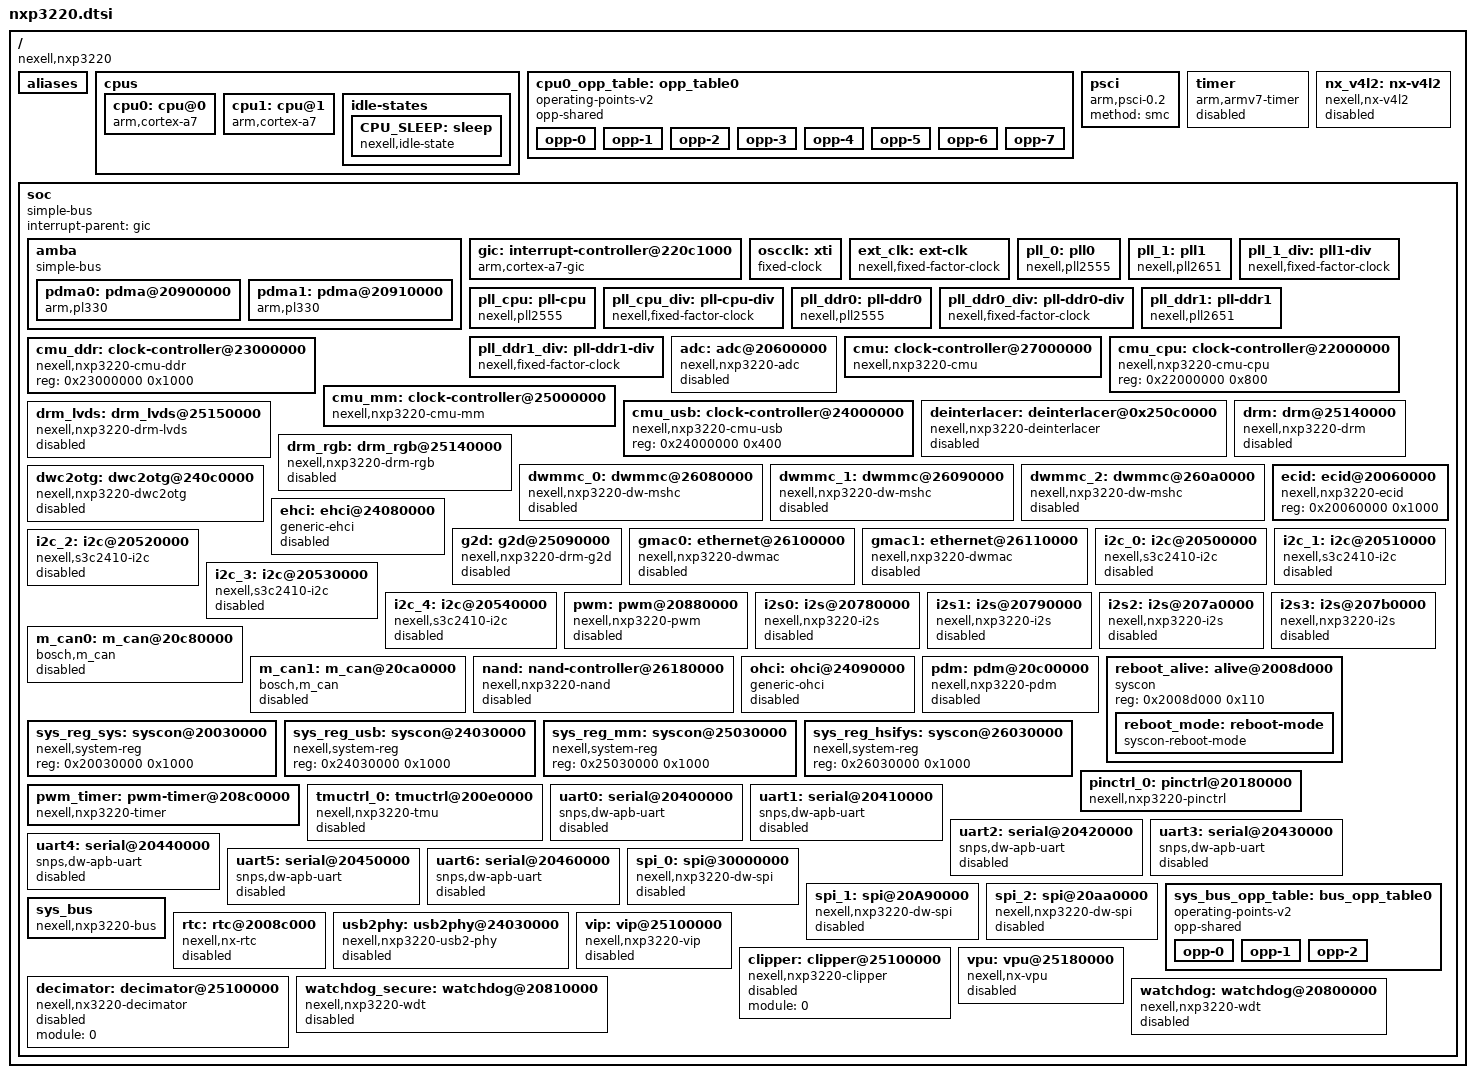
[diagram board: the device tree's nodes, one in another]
// SPDX-License-Identifier: (GPL-2.0+ OR MIT)

#include <dt-bindings/interrupt-controller/arm-gic.h>
#include <dt-bindings/clock/nxp3220-clk.h>
#include <dt-bindings/media/nxp3220-vip.h>
#include <dt-bindings/soc/nexell,boot-mode.h>
#include <dt-bindings/reset/nexell,nxp3220-reset.h>

#define CLK_SET_RATE_PARENT     (1<<2)

/ {
	compatible = "nexell,nxp3220";
	#address-cells = <0x1>;
	#size-cells = <0x1>;

	aliases {
		pinctrl0 = &pinctrl_0;
		serial0 = &uart0;
		serial1 = &uart1;
		serial2 = &uart2;
		serial3 = &uart3;
		serial4 = &uart4;
		serial5 = &uart5;
		serial6 = &uart6;
		i2c0 = &i2c_0;
		i2c1 = &i2c_1;
		i2c2 = &i2c_2;
		i2c3 = &i2c_3;
		i2c4 = &i2c_4;
		spi0 = &spi_0;
		spi1 = &spi_1;
		spi2 = &spi_2;
		ethernet0 = &gmac0;
		ethernet1 = &gmac1;
	};

	cpus {
		#address-cells = <1>;
		#size-cells = <0>;

		cpu0: cpu@0 {
			device_type = "cpu";
			compatible = "arm,cortex-a7";
			reg = <0>;
			clocks = <&pll_cpu_div 0>;
			clock-names = "cpu";
			clock-frequency = <800000000>;
			operating-points-v2 = <&cpu0_opp_table>;
			#cooling-cells = <2>;
			cpu-idle-states = <&CPU_SLEEP>;
		};

		cpu1: cpu@1 {
			device_type = "cpu";
			compatible = "arm,cortex-a7";
			reg = <1>;
			clock-frequency = <800000000>;
			operating-points-v2 = <&cpu0_opp_table>;
			cpu-idle-states = <&CPU_SLEEP>;
		};

		idle-states {
			CPU_SLEEP: sleep {
				compatible = "nexell,idle-state";
				entry-latency-us = <150>;
				exit-latency-us = <200>;
				min-residency-us = <2000>;
			};
		};
	};

	cpu0_opp_table: opp_table0 {
		compatible = "operating-points-v2";
		opp-shared;

		opp-0 {
			opp-hz = /bits/ 64 <100000000>;
			opp-microvolt = <1000000>;
		};
		opp-1 {
			opp-hz = /bits/ 64 <200000000>;
			opp-microvolt = <1000000>;
		};
		opp-2 {
			opp-hz = /bits/ 64 <300000000>;
			opp-microvolt = <1000000>;
		};
		opp-3 {
			opp-hz = /bits/ 64 <400000000>;
			opp-microvolt = <1000000>;
		};
		opp-4 {
			opp-hz = /bits/ 64 <500000000>;
			opp-microvolt = <1000000>;
		};
		opp-5 {
			opp-hz = /bits/ 64 <600000000>;
			opp-microvolt = <1000000>;
		};
		opp-6 {
			opp-hz = /bits/ 64 <700000000>;
			opp-microvolt = <1000000>;
		};
		opp-7 {
			opp-hz = /bits/ 64 <800000000>;
			opp-microvolt = <1000000>;
			opp-suspend;
		};
	};

	psci {
		compatible = "arm,psci-0.2";
		method = "smc";
	};

	timer {
		status = "disabled";

		compatible = "arm,armv7-timer";
		interrupt-parent = <&gic>;
		interrupts = <GIC_PPI 13 (GIC_CPU_MASK_SIMPLE(2) |
					  IRQ_TYPE_LEVEL_LOW)>,
			     <GIC_PPI 14 (GIC_CPU_MASK_SIMPLE(2) |
					  IRQ_TYPE_LEVEL_LOW)>,
			     <GIC_PPI 11 (GIC_CPU_MASK_SIMPLE(2) |
					  IRQ_TYPE_LEVEL_LOW)>,
			     <GIC_PPI 10 (GIC_CPU_MASK_SIMPLE(2) |
					  IRQ_TYPE_LEVEL_LOW)>;
		always-on = <1>;
		clock-frequency = <24000000>;
		arm,cpu-registers-not-fw-configured;
	};

	nx_v4l2: nx-v4l2 {
		compatible = "nexell,nx-v4l2";
		status = "disabled";
	};

	soc: soc {
		compatible = "simple-bus";
		#address-cells = <1>;
		#size-cells = <1>;
		interrupt-parent = <&gic>;
		ranges;

		amba {
			#address-cells = <1>;
			#size-cells = <1>;
			compatible = "simple-bus";
			ranges;

			pdma0: pdma@20900000 {
				compatible = "arm,pl330", "arm,primecell";
				reg = <0x20900000 0x1000>;
				clocks = <&cmu CLK_DMA0_APB>,
				         <&cmu CLK_DMA0_AXI>,
				         <&cmu CLK_DMA_BUS0_AXI>;
				clock-names = "apb_pclk", "axi_clk", "axi_bclk";
				interrupts = <GIC_SPI 35 IRQ_TYPE_NONE>, <GIC_SPI 34 IRQ_TYPE_NONE>;
				#dma-cells = <1>;
				dma-channels = <8>;
				dma-requests = <32>;
			};

			pdma1: pdma@20910000 {
				compatible = "arm,pl330", "arm,primecell";
				reg = <0x20910000 0x1000>;
				clocks = <&cmu CLK_DMA1_APB>,
				         <&cmu CLK_DMA1_AXI>,
				         <&cmu CLK_DMA_BUS0_AXI>;
				clock-names = "apb_pclk", "axi_clk", "axi_bclk";
				interrupts = <GIC_SPI 37 IRQ_TYPE_NONE>, <GIC_SPI 36 IRQ_TYPE_NONE>;
				#dma-cells = <1>;
				dma-channels = <8>;
				dma-requests = <32>;
			};
		};

		gic: interrupt-controller@220c1000 {
			compatible = "arm,cortex-a7-gic";
			reg = <0x220c1000 0x1000>,
			      <0x220c2000 0x1000>,
			      <0x220c4000 0x2000>,
			      <0x220c6000 0x2000>;
			interrupt-controller;
			#interrupt-cells = <3>;
		};

		oscclk: xti {
			compatible = "fixed-clock";
			#clock-cells = <0>;
			clock-output-names = "oscclk";
			clock-frequency =  <24000000>;
		};

		ext_clk: ext-clk {
			compatible = "nexell,fixed-factor-clock";
			#clock-cells = <0>;
			clock-div = <2>;
			clock-mult = <1>;
			clocks = <&oscclk>;
			clock-output-names = "ext_clk";
		};

		/* System bus and Io */
		pll_0: pll0 {
			compatible = "nexell,pll2555", "syscon";
			reg = <0x27020000 0x60>;
			#clock-cells = <1>;
			clocks = <&oscclk>;
			clock-output-names = "pll0";
			assigned-clocks = <&pll_0 0>;
			assigned-clock-rates = <1000000000>;
		};

		pll_1: pll1 {
			compatible = "nexell,pll2651", "syscon";
			reg = <0x27030000 0x60>;
			#clock-cells = <1>;
			clocks = <&oscclk>;
			clock-output-names = "pll1";
		};

		/* Audio sample rate 48Khz */
		pll_1_div: pll1-div {
			compatible = "nexell,fixed-factor-clock";
			#clock-cells = <0>;
			clock-div = <2>;
			clock-mult = <1>;
			clock-flags = <CLK_SET_RATE_PARENT>;
			clocks = <&pll_1 0>;
			clock-output-names = "pll1_div";

			assigned-clocks = <&pll_1 0>;
			assigned-clock-rates = <1228800000>;
		};

		pll_cpu: pll-cpu {
			compatible = "nexell,pll2555", "syscon";
			reg = <0x22070000 0x60>;
			#clock-cells = <1>;
			clocks = <&oscclk>;
			clock-output-names = "pll_cpu";
		};

		/* CPU DVFS */
		pll_cpu_div: pll-cpu-div {
			compatible = "nexell,fixed-factor-clock";
			#clock-cells = <0>;
			clock-div = <1>;
			clock-mult = <1>;
			clock-flags = <CLK_SET_RATE_PARENT>;
			clocks = <&pll_cpu 0>;
			clock-output-names = "pll_cpu_div";
			assigned-clocks = <&pll_cpu 0>;
			assigned-clock-rates = <800000000>;
		};

		pll_ddr0: pll-ddr0 {
			compatible = "nexell,pll2555", "syscon";
			reg = <0x23070000 0x60>;
			#clock-cells = <1>;
			clocks = <&oscclk>;
			clock-output-names = "pll_ddr0";
		};

		/* DDR Memory and IO: Set by bootloader */
		pll_ddr0_div: pll-ddr0-div {
			compatible = "nexell,fixed-factor-clock";
			#clock-cells = <0>;
			clock-div = <2>;
			clock-mult = <1>;
			clock-flags = <CLK_SET_RATE_PARENT>;
			clocks = <&pll_ddr0 0>;
			clock-output-names = "pll_ddr0_div";
		};

		pll_ddr1: pll-ddr1 {
			compatible = "nexell,pll2651", "syscon";
			reg = <0x23080000 0x60>;
			#clock-cells = <1>;
			clocks = <&oscclk>;
			clock-output-names = "pll_ddr1";
		};

		/* Audio sample rate 44.1Khz */
		pll_ddr1_div: pll-ddr1-div {
			compatible = "nexell,fixed-factor-clock";
			#clock-cells = <0>;
			clock-div = <2>;
			clock-mult = <1>;
			clocks = <&pll_ddr1 0>;
			clock-flags = <CLK_SET_RATE_PARENT>;
			clock-output-names = "pll_ddr1_div";

			assigned-clocks = <&pll_ddr1 0>;
			assigned-clock-rates = <1354752000>;
		};

		adc: adc@20600000 {
			compatible = "nexell,nxp3220-adc";
			reg = <0x20600000 0x1000>;
			interrupts = <GIC_SPI 0 IRQ_TYPE_NONE>;
			clocks = <&cmu CLK_ADC0_APB>;
			clock-names = "adc";
			sample_rate = <200000>;
			#io-channel-cells = <1>;
			status = "disabled";
		};

		cmu: clock-controller@27000000 {
			compatible = "nexell,nxp3220-cmu";
			reg = <0x27000000 0x8000>,
			    <0x27010000 0x8000>;
			#clock-cells = <1>;
			#reset-cells = <1>;

			assigned-clocks = <&cmu CLK_SRC_SYS0_AXI>,
					  <&cmu CLK_SYS_DIV_SYS0_AXI>,
					  <&cmu CLK_SRC_TIMER0_APB>,
					  <&cmu CLK_SRC_TIMER0_TCLK0>,
					  <&cmu CLK_SRC_TIMER0_TCLK1>,
					  <&cmu CLK_SRC_TIMER0_TCLK2>,
					  <&cmu CLK_SRC_I2C0_APB>,
					  <&cmu CLK_SRC_USB0_AHB>,
					  <&cmu CLK_SRC_SPI0_APB>,
					  <&cmu CLK_SRC_SPI0_CORE>,
					  <&cmu CLK_SRC_PWM0_APB>,
					  <&cmu CLK_SRC_UART0_CORE>,
					  <&cmu CLK_SRC_UART0_APB>,
					  <&cmu CLK_SYS_DIV_SYS0_HSIF_APB>,
					  <&cmu CLK_SYS_DIV_SYS0_HSIF_AXI>,
					  <&cmu CLK_SYS_DIV_I2C0_APB>;

			assigned-clock-parents = <&pll_0 0>,	/* SRC_SYS0_AXI */
						 <0>,		/* SYS_DIV_SYS0_AXI */
						 <&pll_0 0>,	/* SRC_TIMER0_APB */
						 <&pll_0 0>,	/* SRC_TIMER0_TCLK0 */
						 <&pll_0 0>,	/* SRC_TIMER0_TCLK1 */
						 <&pll_0 0>,	/* SRC_TIMER0_TCLK2 */
						 <&pll_0 0>,	/* SRC_I2C0_APB */
						 <&pll_0 0>,	/* SRC_USB0_AHB */
						 <&pll_0 0>,	/* SRC_SPI0_APB */
						 <&pll_0 0>,	/* SRC_SPI0_CORE */
						 <&pll_0 0>,	/* SRC_PWM0_APB */
						 <&pll_0 0>,	/* SRC_UART0_CORE */
						 <&pll_0 0>,	/* SRC_UART0_APB */
						 <0>,		/* SYS_DIV_SYS0_HSIF_APB */
						 <0>,		/* SYS_DIV_SYS0_HSIF_AXI */
						 <0>;		/* SYS_DIV_I2C0_APB */

			assigned-clock-rates = <333333334>,     /* SRC_SYS0_AXI */
					       <333333334>,     /* SYS_DIV_SYS0_AXI */
					       <100000000>,     /* SRC_TIMER0_APB */
					       <0>,             /* SRC_TIMER0_TCLK0 */
					       <0>,             /* SRC_TIMER0_TCLK1 */
					       <0>,             /* SRC_TIMER0_TCLK2 */
					       <0>,             /* SRC_I2C0_APB */
					       <250000000>,     /* SRC_USB0_AHB */
					       <0>,             /* SRC_SPI0_APB */
					       <0>,             /* SRC_SPI0_CORE */
					       <0>,             /* SRC_PWM0_APB */
					       <0>,             /* SRC_UART0_CORE */
					       <0>,             /* SRC_UART0_APB */
					       <125000000>,     /* SYS_DIV_SYS0_HSIF_APB */
					       <250000000>,     /* SYS_DIV_SYS0_HSIF_AXI */
					       <100000000>;	/* SYS_DIV_I2C0_APB */
		};

		cmu_cpu: clock-controller@22000000 {
			compatible = "nexell,nxp3220-cmu-cpu";
			reg = <0x22000000 0x800>;
			#clock-cells = <1>;
		};

		cmu_ddr: clock-controller@23000000 {
			compatible = "nexell,nxp3220-cmu-ddr";
			reg = <0x23000000 0x1000>;
			#clock-cells = <1>;
		};

		cmu_mm: clock-controller@25000000 {
			compatible = "nexell,nxp3220-cmu-mm";
			reg = <0x25000000 0x1000>;
			#clock-cells = <1>;
			#reset-cells = <1>;
			assigned-clocks = <&cmu_mm CLK_MM_DIV_AXI>,
					  <&cmu_mm CLK_MM_DIV_APB>;
			assigned-clock-rates = <333333334>, <166666667>;
		};

		cmu_usb: clock-controller@24000000 {
			compatible = "nexell,nxp3220-cmu-usb";
			reg = <0x24000000 0x400>;
			#clock-cells = <1>;
		};

		deinterlacer: deinterlacer@0x250c0000 {
			compatible ="nexell,nxp3220-deinterlacer";
			reg = <0x250C0000 0x1000>;
			interrupts = <GIC_SPI 33 IRQ_TYPE_NONE>;
			assigned-clocks = <&cmu_mm CLK_MM_DEINTERLACE_AXI>,
				<&cmu_mm CLK_MM_DEINTERLACE_APB>;
			assigned-clock-rates = <333333334>, <166666667>;
			clock-names = "axi","apb";
			clocks = <&cmu_mm CLK_MM_DEINTERLACE_AXI>,
				<&cmu_mm CLK_MM_DEINTERLACE_APB>;
			status = "disabled";
		};

		drm: drm@25140000 {
			compatible = "nexell,nxp3220-drm";
			reg = <0x25140000 0x1000>, <0x25140800 0x1000>;
			reg-names = "mlc.0", "dpc.0";
			interrupts = <GIC_SPI 38 IRQ_TYPE_NONE>;
#if 0
			assigned-clocks = <&cmu CLK_SRC_DPC0_X2>,
					  <&cmu_mm CLK_MM_DPC_AXI>,
					  <&pll_0 0>;
			assigned-clock-parents = <&pll_0 0>, <0>, <0>;
			assigned-clock-rates = <0>, <333333334>, <0>;
#endif

			assigned-clocks = <&cmu CLK_SRC_DPC0_X2> , <&cmu_mm CLK_MM_DPC_AXI>, <&pll_0 0>;
			assigned-clock-parents = <&pll_ddr0_div 0> , <0>, <0>;
			assigned-clock-rates = <0>, <333333334>, <0>;
			clocks = <&cmu_mm CLK_MM_DPC_AXI>,
			       <&cmu_mm CLK_MM_DPC_X1>,
			       <&cmu_mm CLK_MM_DPC_X2>;
			clock-names = "axi", "clk_x1", "clk_x2";
			plane-names = "primary", "video";
			status = "disabled";
		};

		drm_lvds: drm_lvds@25150000 {
			compatible = "nexell,nxp3220-drm-lvds";
			reg = <0x25150000 0x1000>;
			assigned-clocks = <&cmu CLK_SRC_LVDS0_VCLK>;
			assigned-clock-parents = <&pll_0 0>;
			assigned-clock-rates = <0>;
			clocks = <&cmu_mm CLK_MM_LVDS_VCLK>,
			       <&cmu_mm CLK_MM_LVDS_PHY>;
			clock-names = "vclk", "phy";
			resets = <&cmu_mm CLK_RESET_MM_LVDS_PHY>;
			status = "disabled";
		};

		drm_rgb: drm_rgb@25140000 {
			compatible = "nexell,nxp3220-drm-rgb";
			syscon = <&sys_reg_sys>;
			pinctrl-names = "default";
			pinctrl-0 = <&dp_vclk &dp_vsync &dp_hsync &dp_de &dp_blue &dp_green &dp_red>;
			status = "disabled";
		};

		dwmmc_0: dwmmc@26080000 {
			compatible = "nexell,nxp3220-dw-mshc";
			interrupts = <GIC_SPI 82 IRQ_TYPE_NONE>;
			#address-cells = <1>;
			#size-cells = <0>;
			reg = <0x26080000 0x1000>;
			clock-names = "biu", "ciu";
			clock-frequency = <400000000>;
			clocks = <&cmu CLK_SDMMC0_AHB>,
			         <&cmu CLK_SDMMC0_CORE>;
			bus-width = <8>;
			pinctrl-names = "default";
			pinctrl-0 = <&mmc0_clk &mmc0_cmd &mmc0_bus8>;
			fifo-depth = <0x20>;
			status = "disabled";
		};

		dwmmc_1: dwmmc@26090000 {
			compatible = "nexell,nxp3220-dw-mshc";
			interrupts = <GIC_SPI 83 IRQ_TYPE_NONE>;
			#address-cells = <1>;
			#size-cells = <0>;
			reg = <0x26090000 0x1000>;
			clock-names = "biu", "ciu";
			clock-frequency = <400000000>;
			clocks = <&cmu CLK_SDMMC1_AHB>,
			         <&cmu CLK_SDMMC1_CORE>;
			bus-width = <4>;
			pinctrl-names = "default";
			pinctrl-0 = <&mmc1_clk &mmc1_cmd &mmc1_bus4>;
			fifo-depth = <0x20>;
			status = "disabled";
		};

		dwmmc_2: dwmmc@260a0000 {
			compatible = "nexell,nxp3220-dw-mshc";
			interrupts = <GIC_SPI 84 IRQ_TYPE_NONE>;
			#address-cells = <1>;
			#size-cells = <0>;
			reg = <0x260a0000 0x1000>;
			clock-names = "biu","ciu";
			clock-frequency = <400000000>;
			clocks = <&cmu CLK_SDMMC2_AHB>,
			         <&cmu CLK_SDMMC2_CORE>;
			fifo-depth = <0x20>;
			bus-width = <4>;
			pinctrl-names = "default";
			pinctrl-0 = <&mmc2_clk &mmc2_cmd &mmc2_bus4>;
			status = "disabled";
		};

		dwc2otg: dwc2otg@240c0000 {
			compatible = "nexell,nxp3220-dwc2otg";
			reg = <0x240c0000 0x11000>;
			interrupts = <GIC_SPI 123 IRQ_TYPE_NONE>;
			clocks = <&cmu_usb CLK_USB_USB20OTG>;
			clock-names = "otg";
			phys = <&usb2phy 0>;
			phy-names = "usb2-phy";
			dr_mode = "otg";
			g-use-dma = <1>;
			g-rx-fifo-size = <1064>;
			g-np-tx-fifo-size = <512>;
			g-tx-fifo-size = <512 512 512 512 256 256 256 256 256
				256 64 64 64 64 64>;
			status = "disabled";
		};

		ecid: ecid@20060000 {
			compatible = "nexell,nxp3220-ecid";
			reg = <0x20060000 0x1000>;
		};

		ehci: ehci@24080000 {
			compatible = "generic-ehci";
			reg = <0x24080000 0x100>;
			interrupts = <GIC_SPI 120 IRQ_TYPE_NONE>;
			clocks = <&cmu_usb CLK_USB_USB20HOST>;
			phys = <&usb2phy 1>, <&usb2phy 2>;
			phy-names = "usb0", "usb1";
			status = "disabled";
		};

		g2d: g2d@25090000 {
			compatible = "nexell,nxp3220-drm-g2d";
			reg = <0x25090000 0x100>;
			interrupts = <GIC_SPI 26 IRQ_TYPE_NONE>; /* 2:AXIM, 26 */
			clocks = <&cmu_mm CLK_MM_G2D_AXI>;
			clock-names = "axi";
			status = "disabled";
		};

		gmac0: ethernet@26100000 {
			compatible = "nexell,nxp3220-dwmac";
			reg = <0x26100000 0x8000>;
			interrupts = <GIC_SPI 39 IRQ_TYPE_NONE>;
			interrupt-names = "macirq0";
			assigned-clocks = <&cmu CLK_SRC_GMAC_RGMII0_PTP_REF>,
					  <&cmu CLK_SRC_GMAC_RGMII0_TX>,
					  <&cmu CLK_GMAC_RGMII0_AXI>,
					  <&cmu CLK_GMAC_RGMII0_APB>,
					  <&cmu CLK_GMAC_RGMII0_PTP_REF>,
					  <&pll_0 0>;
			assigned-clock-parents = <&pll_0 0>,
						 <&pll_0 0>,
						 <0>, <0>, <0>;
			assigned-clock-rates = <25000000>,
					       <125000000>,
					       <250000000>,
					       <125000000>,
					       <25000000>;
			clocks = <&cmu CLK_GMAC_RGMII0_AXI>,
				 <&cmu CLK_GMAC_RGMII0_APB>,
				 <&cmu CLK_GMAC_RGMII0_TX>,
				 <&cmu CLK_GMAC_RGMII0_PTP_REF>;
			clock-names = "master_bus", "slave_bus", "tx", "ptp_ref";
			status = "disabled";

			snps,write-requests = <3>;
			snps,read-requests = <3>;
			snps,burst-map = <0x4>;
			snps,txpbl = <32>;
			snps,rxpbl = <32>;
			snps,no-pbl-x8;
		};

		gmac1: ethernet@26110000 {
			compatible = "nexell,nxp3220-dwmac";
			reg = <0x26110000 0x8000>;
			interrupts = <GIC_SPI 42 IRQ_TYPE_NONE>;
			interrupt-names = "macirq1";
			assigned-clocks = <&cmu CLK_SRC_GMAC_RMII0_PTP_REF>,
					  <&cmu CLK_GMAC_RMII0_AXI>,
					  <&cmu CLK_GMAC_RMII0_APB>,
					  <&cmu CLK_GMAC_RMII0_PTP_REF>,
					  <&pll_0 0>;
			assigned-clock-parents = <&pll_0 0>;
			assigned-clock-rates = <25000000>,
					       <250000000>,
					       <125000000>,
					       <25000000>;
			clocks = <&cmu CLK_GMAC_RMII0_AXI>,
				 <&cmu CLK_GMAC_RMII0_APB>,
				 <&cmu CLK_GMAC_RMII0_PTP_REF>;
			clock-names = "master_bus", "slave_bus", "ptp_ref";
			status = "disabled";

			snps,write-requests = <3>;
			snps,read-requests = <3>;
			snps,burst-map = <0x4>;
			snps,txpbl = <32>;
			snps,rxpbl = <32>;
			snps,no-pbl-x8;
		};

		i2c_0: i2c@20500000 {
			compatible = "nexell,s3c2410-i2c";
			reg = <0x20500000 0x100>;
			interrupts = <GIC_SPI 52 IRQ_TYPE_NONE>;
			clock-names = "i2c";
			clocks = <&cmu CLK_I2C0_APB>;
			pinctrl-names = "default";
			pinctrl-0 = <&i2c0_bus>;
			status = "disabled";
		};

		i2c_1: i2c@20510000 {
			compatible = "nexell,s3c2410-i2c";
			reg = <0x20510000 0x100>;
			interrupts = <GIC_SPI 53 IRQ_TYPE_NONE>;
			clock-names = "i2c";
			clocks = <&cmu CLK_I2C1_APB>;
			pinctrl-names = "default";
			pinctrl-0 = <&i2c1_bus>;
			status = "disabled";
		};

		i2c_2: i2c@20520000 {
			compatible = "nexell,s3c2410-i2c";
			reg = <0x20520000 0x100>;
			interrupts = <GIC_SPI 54 IRQ_TYPE_NONE>;
			clock-names = "i2c";
			clocks = <&cmu CLK_I2C2_APB>;
			pinctrl-names = "default";
			pinctrl-0 = <&i2c2_bus>;
			status = "disabled";
		};

		i2c_3: i2c@20530000 {
			compatible = "nexell,s3c2410-i2c";
			reg = <0x20530000 0x100>;
			interrupts = <GIC_SPI 55 IRQ_TYPE_NONE>;
			clock-names = "i2c";
			clocks = <&cmu CLK_I2C3_APB>;
			pinctrl-names = "default";
			pinctrl-0 = <&i2c3_bus>;
			status = "disabled";
		};

		i2c_4: i2c@20540000 {
			compatible = "nexell,s3c2410-i2c";
			reg = <0x20540000 0x100>;
			interrupts = <GIC_SPI 56 IRQ_TYPE_NONE>;
			clock-names = "i2c";
			clocks = <&cmu CLK_I2C4_APB>;
			pinctrl-names = "default";
			pinctrl-0 = <&i2c4_bus>;
			status = "disabled";
		};

		pwm: pwm@20880000 {
			compatible = "nexell,nxp3220-pwm";
			reg = <0x20880000 0x400>;
			assigned-clocks = <&cmu CLK_SRC_PWM0_TCLK0>,
					  <&cmu CLK_SRC_PWM0_TCLK1>,
					  <&cmu CLK_SRC_PWM0_TCLK2>,
					  <&cmu CLK_SRC_PWM0_TCLK3>,
					  <&cmu CLK_PWM0_APB>,
					  <&pll_0 0>;
			assigned-clock-rates = <0>, <0>, <0>, <0>, <166000000>,
					       <0>;
			assigned-clock-parents = <&pll_0 0>, <&pll_0 0>,
						 <&pll_0 0>, <&pll_0 0>,
						 <0>, <0>;
			clocks = <&cmu CLK_PWM0_APB>,
				 <&cmu CLK_PWM0_TCLK0>,
				 <&cmu CLK_PWM0_TCLK1>,
				 <&cmu CLK_PWM0_TCLK2>,
				 <&cmu CLK_PWM0_TCLK3>;
			clock-names = "pwm_apb", "pwm_tclk0", "pwm_tclk1",
				      "pwm_tclk2", "pwm_tclk3";
			nexell,pwm-outputs = <0>, <1>, <2>, <3>;
			tclk_freq = <100000000>, <100000000>, <100000000>, <100000000>;
			#pwm-cells = <3>;
			pinctrl-names = "default";
			pinctrl-0 = <&pwm0_pin &pwm1_pin &pwm2_pin &pwm3_pin>;
			status = "disabled";
		};

		i2s0: i2s@20780000 {
			compatible = "nexell,nxp3220-i2s";
			#sound-dai-cells = <0>;
			reg = <0x20780000 0x1000>;
			assigned-clocks = <&cmu CLK_SRC_I2S0_CORE>,
					<&cmu CLK_I2S0_CORE>;
			assigned-clock-parents = <&pll_1_div 0>, <0>;
			assigned-clock-rates = <0>, <12288000>;
			clocks = <&cmu CLK_I2S0_CORE>, <&cmu CLK_I2S0_APB>;
			clock-names = "i2s", "pclk";
			dmas = <&pdma0 5 &pdma0 4>;
			dma-names = "tx", "rx";
			pinctrl-names = "default";
			pinctrl-0 = <&i2s0_bus>;
			status = "disabled";
		};

		i2s1: i2s@20790000 {
			compatible = "nexell,nxp3220-i2s";
			#sound-dai-cells = <0>;
			reg = <0x20790000 0x1000>;
			assigned-clocks = <&cmu CLK_SRC_I2S1_CORE>,
					<&cmu CLK_I2S1_CORE>;
			assigned-clock-parents = <&pll_1_div 0>, <0>;
			assigned-clock-rates = <0>, <12288000>;
			clocks = <&cmu CLK_I2S1_CORE>, <&cmu CLK_I2S1_APB>;
			clock-names = "i2s", "pclk";
			dmas = <&pdma1 5 &pdma1 4>;
			dma-names = "tx", "rx";
			pinctrl-names = "default";
			pinctrl-0 = <&i2s1_bus>;
			status = "disabled";
		};

		i2s2: i2s@207a0000 {
			compatible = "nexell,nxp3220-i2s";
			#sound-dai-cells = <0>;
			reg = <0x207a0000 0x1000>;
			assigned-clocks = <&cmu CLK_SRC_I2S2_CORE>,
					<&cmu CLK_I2S2_CORE>;
			assigned-clock-parents = <&pll_1_div 0>, <0>;
			assigned-clock-rates = <0>, <12288000>;
			clocks = <&cmu CLK_I2S2_CORE>, <&cmu CLK_I2S2_APB>;
			clock-names = "i2s", "pclk";
			dmas = <&pdma0 7 &pdma0 6>;
			dma-names = "tx", "rx";
			pinctrl-names = "default";
			pinctrl-0 = <&i2s2_bus>;
			status = "disabled";
		};

		i2s3: i2s@207b0000 {
			compatible = "nexell,nxp3220-i2s";
			#sound-dai-cells = <0>;
			reg = <0x207b0000 0x1000>;
			assigned-clocks = <&cmu CLK_SRC_I2S3_CORE>,
					<&cmu CLK_I2S3_CORE>;
			assigned-clock-parents = <&pll_1_div 0>, <0>;
			assigned-clock-rates = <0>, <12288000>;
			clocks = <&cmu CLK_I2S3_CORE>, <&cmu CLK_I2S3_APB>;
			clock-names = "i2s", "pclk";
			dmas = <&pdma1 7 &pdma1 6>;
			dma-names = "tx", "rx";
			pinctrl-names = "default";
			pinctrl-0 = <&i2s3_bus>;
			status = "disabled";
		};

		m_can0: m_can@20c80000 {
			compatible = "bosch,m_can";
			reg = <0x20c80000 0x4000>, <0x20c90000 0x2200>;
			reg-names = "m_can", "message_ram";
			interrupts = <GIC_SPI 27 IRQ_TYPE_NONE>;
			interrupt-names = "int0";
			assigned-clocks = <&cmu CLK_SRC_CAN0_CORE>,
					  <&cmu CLK_CAN0_CORE>,
					  <&pll_0 0>;
			assigned-clock-parents = <&pll_0 0>, <0>, <0>;
			assigned-clock-rates = <0>, <10000000>, <0>;
			clocks = <&cmu CLK_CAN0_APB>, <&cmu CLK_CAN0_CORE>;
			clock-names = "hclk", "cclk";
			pinctrl-names = "default";
			pinctrl-0 = <&mcan0_bus>;
			bosch,mram-cfg = <0x0 0 0 64 0 0 32 32>;
			status = "disabled";
		};

		m_can1: m_can@20ca0000 {
			compatible = "bosch,m_can";
			reg = <0x20ca0000 0x4000>, <0x20cb0000 0x2200>;
			reg-names = "m_can", "message_ram";
			interrupts = <GIC_SPI 29 IRQ_TYPE_NONE>;
			interrupt-names = "int0";
			assigned-clocks = <&cmu CLK_SRC_CAN1_CORE>,
					  <&cmu CLK_CAN1_CORE>,
					  <&pll_0 0>;
			assigned-clock-parents = <&pll_0 0>, <0>, <0>;
			assigned-clock-rates = <0>, <10000000>, <0>;
			clocks = <&cmu CLK_CAN1_APB>, <&cmu CLK_CAN1_CORE>;
			clock-names = "hclk", "cclk";
			pinctrl-names = "default";
			pinctrl-0 = <&mcan1_bus>;
			bosch,mram-cfg = <0x0 0 0 64 0 0 32 32>;
			status = "disabled";
		};

		nand: nand-controller@26180000 {
			compatible = "nexell,nxp3220-nand";
			reg = <0x26180000 0x1000>;
			clocks = <&cmu CLK_NANDC0_APB>, <&cmu CLK_NANDC0_AXI>;
			clock-names = "nand_apb", "nand_core";
			interrupts = <GIC_SPI 66 IRQ_TYPE_NONE>;
			assigned-clocks = <&cmu CLK_SRC_NANDC0_AXI>,
					  <&cmu CLK_NANDC0_AXI>,
					  <&cmu CLK_NANDC0_APB>;
			assigned-clock-parents = <&pll_0 0>, <0>, <0>;
			assigned-clock-rates = <250000000>, <250000000>, <125000000>;
			pinctrl-names = "default";
			pinctrl-0 = <&nand_data>, <&nand_cs0>;
			nand-bus-width = <8>;
			nand-on-flash-bbt;
			nand-ecc-mode = "hw_syndrome";
			status = "disabled";
		};

		ohci: ohci@24090000 {
			compatible = "generic-ohci";
			reg = <0x24090000 0x100>;
			interrupts = <GIC_SPI 122 IRQ_TYPE_NONE>;
			clocks = <&cmu_usb CLK_USB_USB20HOST>;
			phys = <&usb2phy 1>, <&usb2phy 2>;
			phy-names = "usb0", "usb1";
			status = "disabled";
		};

		pdm: pdm@20c00000 {
			compatible = "nexell,nxp3220-pdm";
			#sound-dai-cells = <0>;
			reg = <0x20c00000 0x1000>, <0x20c04000 0x4000>;
			reg-names = "pdm", "sram";
			assigned-clocks = <&cmu CLK_SRC_PDM0_AXI>,
					  <&cmu CLK_SRC_PDM0_CORE>,
					  <&cmu CLK_PDM0_AXI>,
					  <&cmu CLK_PDM0_CORE>;
			assigned-clock-parents = <&pll_1_div 0>,
						 <&pll_1_div 0>,
						 <0>,
						 <0>;
			assigned-clock-rates = <0>, <0>, <200000000>, <0>;
			clocks = <&cmu CLK_PDM0_AXI>,
			       <&cmu CLK_PDM0_CORE>;
			clock-names = "axi", "core";
			interrupts = <GIC_SPI 67 IRQ_TYPE_NONE>;
			pinctrl-names = "default";
			pinctrl-0 = <&pdm_strobe>, <&pdm_lr0>, <&pdm_lr1>;
			syscon = <&sys_reg_sys>;
			status = "disabled";
		};

		reboot_alive: alive@2008d000 {
			compatible = "syscon", "simple-mfd";
			reg = <0x2008d000 0x110>;

			reboot_mode: reboot-mode {
				compatible = "syscon-reboot-mode";
				offset = <0xd8>;	/* ALIVE_SCRATCHRSTREG4 */

				mode-normal	= <BOOT_NORMAL>;
				mode-bootloader	= <BOOT_FASTBOOT>;
				mode-recovery	= <BOOT_RECOVERY>;
				mode-dfu	= <BOOT_DFU>;
			};
		};

		sys_reg_sys: syscon@20030000 {
			compatible = "nexell,system-reg", "syscon",
				     "simple-mfd";
			reg = <0x20030000 0x1000>;
		};

		sys_reg_usb: syscon@24030000 {
			compatible = "nexell,system-reg","syscon",
				     "simple-mfd";
			reg = <0x24030000 0x1000>;
		};

		sys_reg_mm: syscon@25030000 {
			compatible = "nexell,system-reg","syscon",
				     "simple-mfd";
			reg = <0x25030000 0x1000>;
		};

		sys_reg_hsifys: syscon@26030000 {
			compatible = "nexell,system-reg","syscon",
				     "simple-mfd";
			reg = <0x26030000 0x1000>;
		};

		pinctrl_0: pinctrl@20180000 {
			compatible = "nexell,nxp3220-pinctrl";
			reg = <0x20180000 0x1000
				0x20190000 0x1000
				0x201a0000 0x1000
				0x201b0000 0x1000
				0x201c0000 0x1000
				0x2008c400 0x1c00>;
			#address-cells = <1>;
			#size-cells = <1>;
			interrupts = <GIC_SPI 45 IRQ_TYPE_NONE>,
				     <GIC_SPI 46 IRQ_TYPE_NONE>,
				     <GIC_SPI 47 IRQ_TYPE_NONE>,
				     <GIC_SPI 48 IRQ_TYPE_NONE>,
				     <GIC_SPI 49 IRQ_TYPE_NONE>,
				     <GIC_SPI 101 IRQ_TYPE_NONE>;
		};

		pwm_timer: pwm-timer@208c0000 {
			status = "okay";

			compatible = "nexell,nxp3220-timer";
			reg = <0x208c0000 0x1000>;
			clocks =  <&cmu CLK_TIMER0_APB>,
				  <&cmu CLK_TIMER0_TCLK0>,
				  <&cmu CLK_TIMER0_TCLK1>,
				  <&cmu CLK_TIMER0_TCLK2>;
			clock-names = "apb", "clksrc", "clkevt0", "clkevt1";
			clksrc-frequency = <100000000>;
			clkevt-frequencies = <100000000>, <100000000>;
			interrupts = <GIC_SPI 107 IRQ_TYPE_NONE>,
				     <GIC_SPI 108 IRQ_TYPE_NONE>;
			clksource = <0>;
			clkevent0 = <1>;
			clkevent1 = <2>;
		};

		tmuctrl_0: tmuctrl@200e0000 {
			compatible = "nexell,nxp3220-tmu";
			reg = <0x200e0000 0x1000>;
			interrupts = <GIC_SPI 110 IRQ_TYPE_NONE>;
			clocks = <&cmu  CLK_TMU0_APB>;
			clock-names = "tmu_apbif";
			#include "nxp3220-tmu-sensor-conf.dtsi"
			status = "disabled";
		};

		uart0: serial@20400000 {
			compatible = "snps,dw-apb-uart";
			reg = <0x20400000 0x1000>;
			interrupts = <GIC_SPI 112 IRQ_TYPE_NONE>;
			reg-shift = <2>;
			reg-io-width = <4>;
			clocks = <&cmu CLK_UART0_CORE>,
				 <&cmu CLK_UART0_APB>;
			clock-names = "baudclk", "apb_pclk";
			clock-frequency =  <100000000>;
			pinctrl-names = "default";
			pinctrl-0 = <&uart0_bus>;
			status = "disabled";
		};

		uart1: serial@20410000 {
			compatible = "snps,dw-apb-uart";
			reg = <0x20410000 0x1000>;
			interrupts = <GIC_SPI 113 IRQ_TYPE_NONE>;
			reg-shift = <2>;
			reg-io-width = <4>;
			clocks = <&cmu CLK_UART1_CORE>,
				 <&cmu CLK_UART1_APB>;
			clock-names = "baudclk", "apb_pclk";
			pinctrl-names = "default";
			pinctrl-0 = <&uart1_bus>;
			status = "disabled";
		};

		uart2: serial@20420000 {
			compatible = "snps,dw-apb-uart";
			reg = <0x20420000 0x1000>;
			interrupts = <GIC_SPI 114 IRQ_TYPE_NONE>;
			reg-shift = <2>;
			reg-io-width = <4>;
			clocks = <&cmu CLK_UART2_CORE>,
				 <&cmu CLK_UART2_APB>;
			clock-names = "baudclk", "apb_pclk";
			clock-frequency =  <100000000>;
			pinctrl-names = "default";
			pinctrl-0 = <&uart2_bus>;
			status = "disabled";
		};

		uart3: serial@20430000 {
			compatible = "snps,dw-apb-uart";
			reg = <0x20430000 0x1000>;
			interrupts = <GIC_SPI 115 IRQ_TYPE_NONE>;
			reg-shift = <2>;
			reg-io-width = <4>;
			clocks = <&cmu CLK_UART3_CORE>,
				 <&cmu CLK_UART3_APB>;
			clock-names = "baudclk", "apb_pclk";
			clock-frequency =  <100000000>;
			pinctrl-names = "default";
			pinctrl-0 = <&uart3_bus>;
			status = "disabled";
		};

		uart4: serial@20440000 {
			compatible = "snps,dw-apb-uart";
			reg = <0x20440000 0x1000>;
			interrupts = <GIC_SPI 116 IRQ_TYPE_NONE>;
			reg-shift = <2>;
			reg-io-width = <4>;
			clocks = <&cmu CLK_UART4_CORE>,
				 <&cmu CLK_UART4_APB>;
			clock-names = "baudclk", "apb_pclk";
			clock-frequency =  <100000000>;
			pinctrl-names = "default";
			pinctrl-0 = <&uart4_bus>;
			status = "disabled";
		};

		uart5: serial@20450000 {
			compatible = "snps,dw-apb-uart";
			reg = <0x20450000 0x1000>;
			interrupts = <GIC_SPI 117 IRQ_TYPE_NONE>;
			reg-shift = <2>;
			reg-io-width = <4>;
			clocks = <&cmu CLK_UART5_CORE>,
				 <&cmu CLK_UART5_APB>;
			clock-names = "baudclk", "apb_pclk";
			clock-frequency =  <100000000>;
			pinctrl-names = "default";
			pinctrl-0 = <&uart5_bus>;
			status = "disabled";
		};

		uart6: serial@20460000 {
			compatible = "snps,dw-apb-uart";
			reg = <0x20460000 0x1000>;
			interrupts = <GIC_SPI 118 IRQ_TYPE_NONE>;
			reg-shift = <2>;
			reg-io-width = <4>;
			clocks = <&cmu CLK_UART6_CORE>,
				 <&cmu CLK_UART6_APB>;
			clock-names = "baudclk", "apb_pclk";
			clock-frequency =  <100000000>;
			pinctrl-names = "default";
			pinctrl-0 = <&uart6_bus>;
			status = "disabled";
		};

		spi_0: spi@30000000 {
			compatible = "nexell,nxp3220-dw-spi";
			reg = <0x30000000 0x1000>;
			interrupts = <GIC_SPI 93 IRQ_TYPE_NONE>;
			assigned-clocks = <&cmu CLK_SPI0_APB>,
					  <&cmu CLK_SPI0_CORE>;
			assigned-clock-rates = <200000000>, <200000000>;
			clocks = <&cmu CLK_SPI0_CORE>,
				<&cmu CLK_SPI0_APB>;
			clock-names = "core", "apb";
			#address-cells = <1>;
			#size-cells = <0>;
			dmas = <&pdma0 0>, <&pdma0 1>;
			dma-names = "tx", "rx";
			num-cs = <1>;
			pinctrl-names = "default";
			pinctrl-0 = <&spi0_bus>;
			status = "disabled";
		};

		spi_1: spi@20A90000 {
			compatible = "nexell,nxp3220-dw-spi";
			reg = <0x20a90000 0x1000>;
			interrupts = <GIC_SPI 94 IRQ_TYPE_NONE>;
			assigned-clocks = <&cmu CLK_SPI1_APB>,
					  <&cmu CLK_SPI1_CORE>;
			assigned-clock-rates = <200000000>, <200000000>;
			clocks = <&cmu CLK_SPI1_CORE>,
				<&cmu CLK_SPI1_APB>;
			clock-names = "core", "apb";
			#address-cells = <1>;
			#size-cells = <0>;
			dmas = <&pdma1 0>, <&pdma1 1>;
			dma-names = "tx", "rx";
			num-cs = <1>;
			pinctrl-names = "default";
			pinctrl-0 = <&spi1_bus>;
			status = "disabled";
		};

		spi_2: spi@20aa0000 {
			compatible = "nexell,nxp3220-dw-spi";
			reg = <0x20aa0000 0x1000>;
			interrupts = <GIC_SPI 95 IRQ_TYPE_NONE>;
			assigned-clocks = <&cmu CLK_SPI2_APB>,
					  <&cmu CLK_SPI2_CORE>;
			assigned-clock-rates = <200000000>, <200000000>;
			clocks = <&cmu CLK_SPI2_CORE>,
				<&cmu CLK_SPI2_APB>;
			clock-names = "core", "apb";
			#address-cells = <1>;
			#size-cells = <0>;
			dmas = <&pdma0 2>, <&pdma0 3>;
			dma-names = "tx", "rx";
			num-cs = <1>;
			pinctrl-names = "default";
			pinctrl-0 = <&spi2_bus>;
			status = "disabled";
		};

		sys_bus_opp_table: bus_opp_table0 {
			compatible = "operating-points-v2";
			opp-shared;

			opp-0 {
				opp-hz = /bits/ 64 <100000000>;
				opp-microvolt = <975000>;
			};
			opp-1 {
				opp-hz = /bits/ 64 <166666667>;
				opp-microvolt = <975000>;
			};
			opp-2 {
				opp-hz = /bits/ 64 <333333334>;
				opp-microvolt = <1000000>;
			};
		};

		sys_bus: sys_bus {
			compatible = "nexell,nxp3220-bus";
			bus-name = "sys";
			clocks = <&cmu CLK_SRC_SYS0_AXI>;
			clock-names = "bus";
			operating-points-v2 = <&sys_bus_opp_table>;
		};

		rtc: rtc@2008c000 {
			compatible = "nexell,nx-rtc";
			reg = <0x2008C000 0x100>;
			interrupts = <GIC_SPI 104 IRQ_TYPE_NONE>;
			status = "disabled";
		};

		usb2phy: usb2phy@24030000 {
			compatible = "nexell,nxp3220-usb2-phy";
			reg = <0x24030000 0x200>;
			#phy-cells = <1>;
			assigned-clocks = <&cmu_usb CLK_USB_AHB>;
			assigned-clock-rates = <250000000>;
			clocks = <&cmu_usb CLK_USB_SYSREG_APB>;
			clock-names = "apb";
			status = "disabled";
		};

		vip: vip@25100000 {
			compatible = "nexell,nxp3220-vip";
			reg = <0x25100000 0x1000>;
			interrupts = <GIC_SPI 124 IRQ_TYPE_NONE>;
			assigned-clocks = <&cmu_mm CLK_MM_VIP_AXI>,
				<&cmu_mm CLK_MM_VIP_APB>;
			assigned-clock-rates = <333333334>, <166666667>;
			clock-names = "vip_axi", "vip_apb";
			clocks = <&cmu_mm CLK_MM_VIP_AXI>,
			       <&cmu_mm CLK_MM_VIP_APB>;
			reset-names = "vip-reset";
			resets = <&cmu_mm CLK_RESET_MM_VIP_AXI>;
			module = <0>;
			status = "disabled";
		};

		clipper: clipper@25100000 {
			compatible = "nexell,nxp3220-clipper";
			module = <0>;
			status = "disabled";
		};

		decimator: decimator@25100000 {
			compatible = "nexell,nx3220-decimator";
			module = <0>;
			status = "disabled";
		};

		vpu: vpu@25180000 {
			compatible = "nexell,nx-vpu";
			reg = <0x25180000 0x10000>;
			interrupts = <GIC_SPI 31 IRQ_TYPE_NONE>;
			clocks = <&cmu_mm CLK_MM_CODA960_AXI>,
				<&cmu_mm CLK_MM_CODA960_APB>,
				<&cmu_mm CLK_MM_CODA960_CORE>;
			clock-names = "vpu-clk-axi", "vpu-clk-apb", "vpu-clk-core";
			assigned-clocks = <&cmu_mm CLK_MM_CODA960_CORE>;
			assigned-clock-rates = <250000000>;
			status = "disabled";
		};

		watchdog_secure: watchdog@20810000 {
			compatible = "nexell,nxp3220-wdt";
			reg = <0x20810000 0x1000>;
			interrupts = <GIC_SPI 89 IRQ_TYPE_NONE>;
			clock-names = "watchdog";
			clocks = <&cmu CLK_SECURE_WDT0_APB>;
			assigned-clocks = <&cmu CLK_SECURE_WDT0_APB>;
			assigned-clock-rates = <140000000>;
			status = "disabled";
		};

		watchdog: watchdog@20800000 {
			compatible = "nexell,nxp3220-wdt";
			reg = <0x20800000 0x1000>;
			interrupts = <GIC_SPI 125 IRQ_TYPE_NONE>;
			clock-names = "watchdog";
			clocks = <&cmu CLK_WDT0_APB>;
			assigned-clocks = <&cmu CLK_WDT0_APB>;
			assigned-clock-rates = <140000000>;
			status = "disabled";
		};
	};
};

#include "nxp3220-pinctrl.dtsi"
